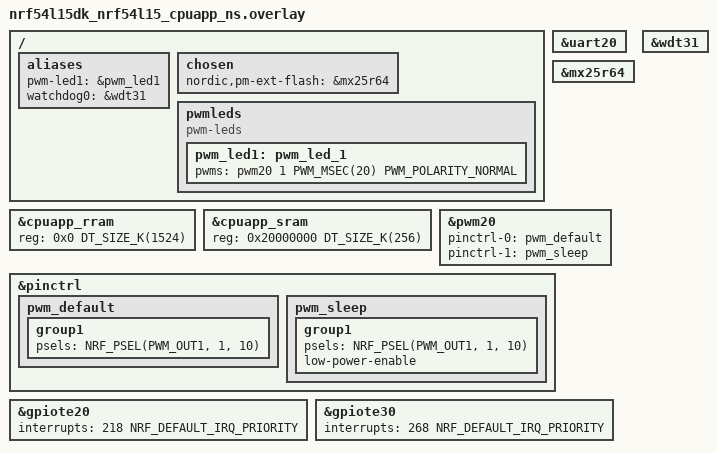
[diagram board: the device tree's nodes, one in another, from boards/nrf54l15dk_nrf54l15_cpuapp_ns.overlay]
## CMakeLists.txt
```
#
# Copyright (c) 2021 Nordic Semiconductor ASA
#
# SPDX-License-Identifier: LicenseRef-Nordic-5-Clause
#

cmake_minimum_required(VERSION 3.20.0)

find_package(Zephyr HINTS $ENV{ZEPHYR_BASE})

project(matter-light-bulb)

# Enable GNU STD support.
include(${ZEPHYR_CONNECTEDHOMEIP_MODULE_DIR}/config/nrfconnect/app/enable-gnu-std.cmake)

# NORDIC SDK APP START

# Include all source files that are located in the Matter common directory.
include(${ZEPHYR_NRF_MODULE_DIR}/samples/matter/common/cmake/source_common.cmake)

# Include Data Model utils
include(${ZEPHYR_NRF_MODULE_DIR}/samples/matter/common/cmake/data_model.cmake)

include(${ZEPHYR_NRF_MODULE_DIR}/samples/matter/common/cmake/zap_helpers.cmake)
ncs_get_zap_parent_dir(ZAP_PARENT_DIR)

target_include_directories(app PRIVATE
    src
    ${ZAP_PARENT_DIR}
)

if(CONFIG_AWS_IOT_INTEGRATION)
    add_subdirectory(src/aws_iot_integration)
endif()

target_sources(app PRIVATE
    src/app_task.cpp
    src/main.cpp
    src/zcl_callbacks.cpp
    ${CHIP_ROOT}/src/app/util/persistence/DeferredAttributePersistenceProvider.cpp
)

ncs_configure_data_model()
# NORDIC SDK APP END
```

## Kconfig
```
#
# Copyright (c) 2022 Nordic Semiconductor
#
# SPDX-License-Identifier: LicenseRef-Nordic-5-Clause
#
mainmenu "Matter nRF Connect Light Bulb Example Application"

# Sample configuration used for Thread networking
if OPENTHREAD

choice OPENTHREAD_NORDIC_LIBRARY_CONFIGURATION
	default OPENTHREAD_NORDIC_LIBRARY_FTD
endchoice

choice OPENTHREAD_DEVICE_TYPE
	default OPENTHREAD_FTD
endchoice

endif # OPENTHREAD

source "${ZEPHYR_CONNECTEDHOMEIP_MODULE_DIR}/config/nrfconnect/chip-module/Kconfig.features"
source "${ZEPHYR_CONNECTEDHOMEIP_MODULE_DIR}/config/nrfconnect/chip-module/Kconfig.defaults"
source "${ZEPHYR_NRF_MODULE_DIR}/samples/matter/common/src/Kconfig"
source "Kconfig.zephyr"
rsource "src/aws_iot_integration/Kconfig"
```

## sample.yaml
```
sample:
  description: Matter Light Bulb example
  name: Matter Light Bulb
tests:
  sample.matter.light_bulb.debug:
    sysbuild: true
    build_only: true
    integration_platforms:
      - nrf52840dk/nrf52840
      - nrf5340dk/nrf5340/cpuapp
      - nrf7002dk/nrf5340/cpuapp
      - nrf54l15dk/nrf54l15/cpuapp
      - nrf54l15dk/nrf54l15/cpuapp/ns
      - nrf54lm20pdk/nrf54lm20a/cpuapp
    platform_allow:
      - nrf52840dk/nrf52840
      - nrf5340dk/nrf5340/cpuapp
      - nrf7002dk/nrf5340/cpuapp
      - nrf54l15dk/nrf54l15/cpuapp
      - nrf54l15dk/nrf54l15/cpuapp/ns
      - nrf54lm20pdk/nrf54lm20a/cpuapp
    tags:
      - sysbuild
      - ci_samples_matter
  sample.matter.light_bulb.release:
    sysbuild: true
    build_only: true
    extra_args:
      - FILE_SUFFIX=release
      - SB_CONFIG_BOOTLOADER_MCUBOOT=y
      - SB_CONFIG_PARTITION_MANAGER=y
    integration_platforms:
      - nrf52840dk/nrf52840
      - nrf5340dk/nrf5340/cpuapp
      - nrf7002dk/nrf5340/cpuapp
      - nrf54l15dk/nrf54l15/cpuapp
      - nrf54lm20pdk/nrf54lm20a/cpuapp
    platform_allow:
      - nrf52840dk/nrf52840
      - nrf5340dk/nrf5340/cpuapp
      - nrf7002dk/nrf5340/cpuapp
      - nrf54l15dk/nrf54l15/cpuapp
      - nrf54lm20pdk/nrf54lm20a/cpuapp
    tags:
      - sysbuild
      - ci_samples_matter
  sample.matter.light_bulb.ffs:
    sysbuild: true
    build_only: true
    extra_args:
      - CONFIG_CHIP_COMMISSIONABLE_DEVICE_TYPE=y
      - CONFIG_CHIP_ROTATING_DEVICE_ID=y
      - CONFIG_CHIP_DEVICE_TYPE=257
    integration_platforms:
      - nrf52840dk/nrf52840
      - nrf5340dk/nrf5340/cpuapp
      - nrf7002dk/nrf5340/cpuapp
      - nrf54l15dk/nrf54l15/cpuapp
      - nrf54lm20pdk/nrf54lm20a/cpuapp
    platform_allow:
      - nrf52840dk/nrf52840
      - nrf5340dk/nrf5340/cpuapp
      - nrf7002dk/nrf5340/cpuapp
      - nrf54l15dk/nrf54l15/cpuapp
      - nrf54lm20pdk/nrf54lm20a/cpuapp
    tags:
      - sysbuild
      - ci_samples_matter
  sample.matter.light_bulb.debug.nrf21540ek:
    sysbuild: true
    build_only: true
    extra_args:
      - light_bulb_SHIELD=nrf21540ek
    integration_platforms:
      - nrf52840dk/nrf52840
    platform_allow: nrf52840dk/nrf52840
    tags:
      - sysbuild
      - ci_samples_matter
  sample.matter.light_bulb.debug.nrf21540ek_fwd:
    sysbuild: true
    build_only: true
    extra_args:
      - light_bulb_SHIELD=nrf21540ek
      - ipc_radio_SHIELD=nrf21540ek
    integration_platforms:
      - nrf5340dk/nrf5340/cpuapp
    platform_allow: nrf5340dk/nrf5340/cpuapp
    tags:
      - sysbuild
      - ci_samples_matter
  # Sample to execute load tests
  sample.matter.light_bulb.memory_profiling.persistent_subscriptions:
    sysbuild: true
    build_only: true
    extra_args:
      - CONFIG_CHIP_PERSISTENT_SUBSCRIPTIONS=y
      - CONFIG_CHIP_MEMORY_PROFILING=y
      - CONFIG_SHELL_MINIMAL=y
    platform_allow:
      - nrf52840dk/nrf52840
      - nrf5340dk/nrf5340/cpuapp
      - nrf54l15dk/nrf54l15/cpuapp
      - nrf7002dk/nrf5340/cpuapp
      - nrf54lm20pdk/nrf54lm20a/cpuapp
    integration_platforms:
      - nrf52840dk/nrf52840
      - nrf5340dk/nrf5340/cpuapp
      - nrf54l15dk/nrf54l15/cpuapp
      - nrf7002dk/nrf5340/cpuapp
      - nrf54lm20pdk/nrf54lm20a/cpuapp
    tags:
      - sysbuild
      - ci_samples_matter
  sample.matter.light_bulb.aws:
    sysbuild: true
    build_only: true
    extra_args:
      - EXTRA_CONF_FILE="overlay-aws-iot-integration.conf"
    platform_allow: nrf7002dk/nrf5340/cpuapp
    integration_platforms:
      - nrf7002dk/nrf5340/cpuapp
    tags:
      - sysbuild
      - ci_samples_matter
```

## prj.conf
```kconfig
#
# Copyright (c) 2022 Nordic Semiconductor ASA
#
# SPDX-License-Identifier: LicenseRef-Nordic-5-Clause
#

# Enable CHIP
CONFIG_CHIP=y
CONFIG_CHIP_PROJECT_CONFIG="src/chip_project_config.h"

# Configure ZAP file name
CONFIG_NCS_SAMPLE_MATTER_ZAP_FILE_PATH="${APPLICATION_CONFIG_DIR}/src/default_zap/light_bulb.zap"

# 32773 == 0x8005 (example lighting-app)
CONFIG_CHIP_DEVICE_PRODUCT_ID=32773
CONFIG_STD_CPP17=y

# Enable Matter pairing automatically on application start.
CONFIG_CHIP_ENABLE_PAIRING_AUTOSTART=y

# Enable Matter extended announcement and increase duration to 1 hour.
CONFIG_CHIP_BLE_EXT_ADVERTISING=y
CONFIG_CHIP_BLE_ADVERTISING_DURATION=60

# Add support for LEDs and buttons on Nordic development kits
CONFIG_DK_LIBRARY=y
CONFIG_PWM=y

# Bluetooth Low Energy configuration
CONFIG_BT_DEVICE_NAME="MatterLight"

# Other settings
CONFIG_THREAD_NAME=y
CONFIG_MPU_STACK_GUARD=y
CONFIG_RESET_ON_FATAL_ERROR=n
CONFIG_CHIP_LIB_SHELL=y
CONFIG_NCS_SAMPLE_MATTER_TEST_SHELL=y

# Reduce application size
CONFIG_USE_SEGGER_RTT=n

# Enable Factory Data feature
CONFIG_CHIP_FACTORY_DATA=y
CONFIG_CHIP_FACTORY_DATA_BUILD=y
```

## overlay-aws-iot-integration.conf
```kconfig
#
# Copyright (c) 2023 Nordic Semiconductor ASA
#
# SPDX-License-Identifier: LicenseRef-Nordic-5-Clause
#

# Enable matter integration layer
CONFIG_AWS_IOT_INTEGRATION=y
CONFIG_AWS_IOT_INTEGRATION_LOG_LEVEL_DBG=y

# AWS IoT library
CONFIG_AWS_IOT=y
CONFIG_AWS_IOT_BROKER_HOST_NAME="xxx.amazonaws.com"
CONFIG_AWS_IOT_CLIENT_ID_STATIC="my-thing"
CONFIG_AWS_IOT_AUTO_DEVICE_SHADOW_REQUEST=n
CONFIG_AWS_IOT_TOPIC_UPDATE_DELTA_SUBSCRIBE=y

# JSON
CONFIG_JSON_LIBRARY=y

# MQTT helper library
CONFIG_MQTT_HELPER_PROVISION_CERTIFICATES=y
CONFIG_MQTT_HELPER_CERTIFICATES_FOLDER="src/aws_iot_integration/certs"
CONFIG_MQTT_HELPER_SEC_TAG=201

# MQTT - Maximum MQTT keepalive timeout specified by AWS IoT Core
CONFIG_MQTT_KEEPALIVE=1200
CONFIG_MQTT_CLEAN_SESSION=y

# MBed TLS
CONFIG_MBEDTLS_HEAP_SIZE=98304
CONFIG_MBEDTLS_RSA_C=y
CONFIG_MBEDTLS_SHA384_C=y
CONFIG_MBEDTLS_SSL_OUT_CONTENT_LEN=1024

# PSA
CONFIG_PSA_WANT_KEY_TYPE_RSA_PUBLIC_KEY=y
CONFIG_PSA_WANT_RSA_KEY_SIZE_2048=y

# Zephyr Networking
CONFIG_NET_CONNECTION_MANAGER=y
CONFIG_NET_DHCPV4=y
CONFIG_NET_IPV4=y
CONFIG_NET_TCP=y
CONFIG_NET_SOCKETS_SOCKOPT_TLS=y
CONFIG_NET_MAX_CONN=8
CONFIG_ZVFS_OPEN_MAX=25

# DNS
CONFIG_ZVFS_EVENTFD_MAX=2
CONFIG_DNS_RESOLVER=y

# Adjust NET configurations to reduce the likelyhood of congestion in the TCP stack when there are
# multiple NET users in the system.
CONFIG_NET_PKT_RX_COUNT=14
CONFIG_NET_PKT_TX_COUNT=14
CONFIG_NET_BUF_RX_COUNT=54
CONFIG_NET_BUF_TX_COUNT=54
CONFIG_NET_TCP_MAX_SEND_WINDOW_SIZE=1024

# Free some memory
CONFIG_SHELL=n
CONFIG_CHIP_LIB_SHELL=n
CONFIG_ASSERT=n
CONFIG_LTO=y
CONFIG_ISR_TABLES_LOCAL_DECLARATION=y
```

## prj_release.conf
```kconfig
#
# Copyright (c) 2022 Nordic Semiconductor ASA
#
# SPDX-License-Identifier: LicenseRef-Nordic-5-Clause
#

# Enable CHIP
CONFIG_CHIP=y
CONFIG_CHIP_PROJECT_CONFIG="src/chip_project_config.h"

# Configure ZAP file name
CONFIG_NCS_SAMPLE_MATTER_ZAP_FILE_PATH="${APPLICATION_CONFIG_DIR}/src/default_zap/light_bulb.zap"

# 32773 == 0x8005 (example lighting-app)
CONFIG_CHIP_DEVICE_PRODUCT_ID=32773
CONFIG_STD_CPP17=y

# Enable Matter pairing automatically on application start.
CONFIG_CHIP_ENABLE_PAIRING_AUTOSTART=y

# Enable Matter extended announcement and increase duration to 1 hour.
CONFIG_CHIP_BLE_EXT_ADVERTISING=y
CONFIG_CHIP_BLE_ADVERTISING_DURATION=60

# Add support for LEDs and buttons on Nordic development kits
CONFIG_DK_LIBRARY=y
CONFIG_PWM=y

# Bluetooth Low Energy configuration
CONFIG_BT_DEVICE_NAME="MatterLight"

# Enable system reset on fatal error
CONFIG_RESET_ON_FATAL_ERROR=y

# Disable all debug features
CONFIG_USE_SEGGER_RTT=n
CONFIG_SHELL=n
CONFIG_OPENTHREAD_SHELL=n
CONFIG_CONSOLE=n
CONFIG_UART_CONSOLE=n
CONFIG_SERIAL=n
CONFIG_LOG=n
CONFIG_LOG_MODE_MINIMAL=n
CONFIG_ASSERT_VERBOSE=n
CONFIG_ASSERT_NO_FILE_INFO=y
CONFIG_PRINTK=n
CONFIG_PRINTK_SYNC=n
CONFIG_THREAD_NAME=n
CONFIG_BOOT_BANNER=n

# Enable Factory Data feature
CONFIG_CHIP_FACTORY_DATA=y
CONFIG_CHIP_FACTORY_DATA_BUILD=y

# Enable Watchdog
CONFIG_NCS_SAMPLE_MATTER_WATCHDOG=y

# Enable LTO to decrease the flash usage.
CONFIG_LTO=y
CONFIG_ISR_TABLES_LOCAL_DECLARATION=y
```

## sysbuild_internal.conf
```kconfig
#
# Copyright (c) 2024 Nordic Semiconductor
#
# SPDX-License-Identifier: LicenseRef-Nordic-5-Clause
#

SB_CONFIG_MATTER=y
SB_CONFIG_PM_OVERRIDE_EXTERNAL_DRIVER_CHECK=n
SB_CONFIG_PM_EXTERNAL_FLASH_MCUBOOT_SECONDARY=n

# Enable the DFU image compression.
SB_CONFIG_MCUBOOT_MODE_OVERWRITE_ONLY=y
SB_CONFIG_MCUBOOT_COMPRESSED_IMAGE_SUPPORT=y
```

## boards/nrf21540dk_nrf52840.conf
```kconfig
#
# Copyright (c) 2022 Nordic Semiconductor ASA
#
# SPDX-License-Identifier: LicenseRef-Nordic-5-Clause
#

# This sample uses Kconfig.defaults to set options common for all
# samples. This file should contain only options specific for this sample
# or overrides of default values.

# Other settings
CONFIG_THREAD_NAME=y
CONFIG_MPU_STACK_GUARD=y
CONFIG_RESET_ON_FATAL_ERROR=n
CONFIG_CHIP_LIB_SHELL=y

# Disable Matter OTA DFU
CONFIG_CHIP_OTA_REQUESTOR=n

# Disable QSPI NOR
CONFIG_CHIP_QSPI_NOR=n

# Disable Factory data feature
CONFIG_CHIP_FACTORY_DATA=n
CONFIG_CHIP_FACTORY_DATA_BUILD=n
```

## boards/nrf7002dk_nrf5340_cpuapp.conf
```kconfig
#
# Copyright (c) 2025 Nordic Semiconductor ASA
#
# SPDX-License-Identifier: LicenseRef-Nordic-5-Clause
#

# Enable LTO to decrease the flash usage.
CONFIG_LTO=y
CONFIG_ISR_TABLES_LOCAL_DECLARATION=y
```

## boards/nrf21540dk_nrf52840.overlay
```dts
/*
 * Copyright (c) 2021-2022 Nordic Semiconductor ASA
 *
 * SPDX-License-Identifier: LicenseRef-Nordic-5-Clause
 */

/ {
	/*
	* By default, PWM module is only configured for led0 (LED1 on the board).
	* The light bulb app, however, uses LED2 to show the state of the lighting,
	* including its brightness level.
	*/
	aliases {
		pwm-led1 = &pwm_led1;
	};

	pwmleds {
		pwm_led1: pwm_led_1 {
			pwms = <&pwm0 1 PWM_MSEC(20) PWM_POLARITY_INVERTED>;
		};
	};

};

&pwm0 {
	pinctrl-0 = <&pwm0_default_alt>;
	pinctrl-1 = <&pwm0_sleep_alt>;
	pinctrl-names = "default", "sleep";
};

&pinctrl {
	pwm0_default_alt: pwm0_default_alt {
		group1 {
			psels = <NRF_PSEL(PWM_OUT1, 0, 14)>;
			nordic,invert;
		};
	};

	pwm0_sleep_alt: pwm0_sleep_alt {
		group1 {
			psels = <NRF_PSEL(PWM_OUT1, 0, 14)>;
			low-power-enable;
		};
	};

};

/* Disable unused peripherals to reduce power consumption */
&adc {
	status = "disabled";
};
&uart1 {
	status = "disabled";
};
&i2c0 {
	status = "disabled";
};
&spi1 {
	status = "disabled";
};
&spi3 {
	status = "disabled";
};
&usbd {
	status = "disabled";
};
```

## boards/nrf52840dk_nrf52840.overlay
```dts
/*
 * Copyright (c) 2021-2022 Nordic Semiconductor ASA
 *
 * SPDX-License-Identifier: LicenseRef-Nordic-5-Clause
 */

/ {
	chosen {
		nordic,pm-ext-flash = &mx25r64;
	};

	/*
	* By default, PWM module is only configured for led0 (LED1 on the board).
	* The light bulb app, however, uses LED2 to show the state of the lighting,
	* including its brightness level.
	*/
	aliases {
		pwm-led1 = &pwm_led1;
	};

	pwmleds {
		pwm_led1: pwm_led_1 {
			pwms = <&pwm0 1 PWM_MSEC(20) PWM_POLARITY_INVERTED>;
		};
	};

};

&pwm0 {
	pinctrl-0 = <&pwm0_default_alt>;
	pinctrl-1 = <&pwm0_sleep_alt>;
	pinctrl-names = "default", "sleep";
};

&pinctrl {
	pwm0_default_alt: pwm0_default_alt {
		group1 {
			psels = <NRF_PSEL(PWM_OUT1, 0, 14)>;
			nordic,invert;
		};
	};

	pwm0_sleep_alt: pwm0_sleep_alt {
		group1 {
			psels = <NRF_PSEL(PWM_OUT1, 0, 14)>;
			low-power-enable;
		};
	};

};

/* Disable unused peripherals to reduce power consumption */
&adc {
	status = "disabled";
};
&uart1 {
	status = "disabled";
};
&i2c0 {
	status = "disabled";
};
&spi1 {
	status = "disabled";
};
&spi3 {
	status = "disabled";
};
&usbd {
	status = "disabled";
};
```

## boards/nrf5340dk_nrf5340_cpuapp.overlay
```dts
/*
 * Copyright (c) 2021-2022 Nordic Semiconductor ASA
 *
 * SPDX-License-Identifier: LicenseRef-Nordic-5-Clause
 */

#include <zephyr/dt-bindings/ipc_service/static_vrings.h>

/ {
	chosen {
		nordic,pm-ext-flash = &mx25r64;
	};

	/*
	* By default, PWM module is only configured for led0 (LED1 on the board).
	* The light bulb app, however, uses LED2 to show the state of the lighting,
	* including its brightness level.
	*/
	aliases {
		pwm-led1 = &pwm_led1;
	};

	pwmleds {
		compatible = "pwm-leds";
		pwm_led1: pwm_led_1 {
			pwms = < &pwm0 1 PWM_MSEC(20) PWM_POLARITY_INVERTED>;
		};
	};
};

/* Set IPC thread priority to the highest value to not collide with other threads. */
&ipc0 {
	zephyr,priority = <0 PRIO_COOP>;
};

&pwm0 {
	pinctrl-0 = <&pwm0_default_alt>;
	pinctrl-1 = <&pwm0_sleep_alt>;
	pinctrl-names = "default", "sleep";
};

&pinctrl {
	pwm0_default_alt: pwm0_default_alt {
		group1 {
			psels = <NRF_PSEL(PWM_OUT1, 0, 29)>;
			nordic,invert;
		};
	};

	pwm0_sleep_alt: pwm0_sleep_alt {
		group1 {
			psels = <NRF_PSEL(PWM_OUT1, 0, 29)>;
			low-power-enable;
		};
	};
};

/* Disable unused peripherals to reduce power consumption */
&adc {
	status = "disabled";
};
&i2c1 {
	status = "disabled";
};
&spi2 {
	status = "disabled";
};
&usbd {
	status = "disabled";
};
```

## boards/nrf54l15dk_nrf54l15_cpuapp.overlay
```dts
/*
 * Copyright (c) 2024 Nordic Semiconductor ASA
 *
 * SPDX-License-Identifier: LicenseRef-Nordic-5-Clause
 */


/ {
	chosen {
		nordic,pm-ext-flash = &mx25r64;
	};

	aliases {
		// Configure PWM module for led1 (LED2 on the board)
		pwm-led1 = &pwm_led1;

		// Use watchdog wdt31 as the application watchdog
		watchdog0 = &wdt31;
	};

	pwmleds {
		compatible = "pwm-leds";
		pwm_led1: pwm_led_1 {
			pwms = <&pwm20 1 PWM_MSEC(20) PWM_POLARITY_NORMAL>;
		};
	};
};

// restore full RRAM and SRAM space - by default some parts are dedicated to FLRP
&cpuapp_rram {
	reg = <0x0 DT_SIZE_K(1524)>;
};

&cpuapp_sram {
	reg = <0x20000000 DT_SIZE_K(256)>;
	ranges = <0x0 0x20000000  0x40000>;
};

// TODO: re-enable HWFC once it's fixed
&uart20 {
	/delete-property/ hw-flow-control;
};

&mx25r64 {
	status = "okay";
};

&pwm20 {
	status = "okay";
	pinctrl-0 = <&pwm_default>;
	pinctrl-1 = <&pwm_sleep>;
	pinctrl-names = "default", "sleep";
};

&pinctrl {
	pwm_default: pwm_default {
		group1 {
			psels = <NRF_PSEL(PWM_OUT1, 1, 10)>;
		};
	};
	pwm_sleep: pwm_sleep {
		group1 {
			psels = <NRF_PSEL(PWM_OUT1, 1, 10)>;
			low-power-enable;
		};
	};
};

&wdt31 {
	status = "okay";
};
```

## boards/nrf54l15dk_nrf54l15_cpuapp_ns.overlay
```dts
/*
 * Copyright (c) 2024 Nordic Semiconductor ASA
 *
 * SPDX-License-Identifier: LicenseRef-Nordic-5-Clause
 */

/ {
	aliases {
		// Configure PWM module for led1 (LED2 on the board)
		pwm-led1 = &pwm_led1;

		// Use watchdog wdt31 as the application watchdog
		watchdog0 = &wdt31;
	};

	chosen {
		nordic,pm-ext-flash = &mx25r64;
	};

	pwmleds {
		compatible = "pwm-leds";
		pwm_led1: pwm_led_1 {
			pwms = <&pwm20 1 PWM_MSEC(20) PWM_POLARITY_NORMAL>;
		};
	};
};

// restore full RRAM and SRAM space - by default some parts are dedicated to FLRP
&cpuapp_rram {
	reg = <0x0 DT_SIZE_K(1524)>;
};

&cpuapp_sram {
	reg = <0x20000000 DT_SIZE_K(256)>;
	ranges = <0x0 0x20000000  0x40000>;
};

// TODO: re-enable HWFC once it's fixed
&uart20 {
	/delete-property/ hw-flow-control;
};

&mx25r64 {
	status = "okay";
};

&pwm20 {
	status = "okay";
	pinctrl-0 = <&pwm_default>;
	pinctrl-1 = <&pwm_sleep>;
	pinctrl-names = "default", "sleep";
};

&pinctrl {
	pwm_default: pwm_default {
		group1 {
			psels = <NRF_PSEL(PWM_OUT1, 1, 10)>;
		};
	};
	pwm_sleep: pwm_sleep {
		group1 {
			psels = <NRF_PSEL(PWM_OUT1, 1, 10)>;
			low-power-enable;
		};
	};
};

&wdt31 {
	status = "okay";
};

// Change IRQ ids to handle button interrupts.

// The default values for nRF54L15 are 219 and 269,
// but with TF-M they are reserved for the secure domain
// (218 and 268 are reserved for the non-secure domain).
&gpiote20 {
	interrupts = <218 NRF_DEFAULT_IRQ_PRIORITY>;
};

&gpiote30 {
	interrupts = <268 NRF_DEFAULT_IRQ_PRIORITY>;
};
```

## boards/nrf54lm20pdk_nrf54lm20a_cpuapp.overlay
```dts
/*
 * Copyright (c) 2025 Nordic Semiconductor ASA
 *
 * SPDX-License-Identifier: LicenseRef-Nordic-5-Clause
 */

/ {
	chosen {
		nordic,pm-ext-flash = &mx25r64;
	};

	aliases {
		// Configure PWM module for led1 (LED2 on the board)
		pwm-led1 = &pwm_led1;

		// Use watchdog wdt31 as the application watchdog
		watchdog0 = &wdt31;
	};

	pwmleds {
		compatible = "pwm-leds";
		pwm_led1: pwm_led_1 {
			pwms = <&pwm20 1 PWM_MSEC(20) PWM_POLARITY_NORMAL>;
		};
	};
};

// restore full RRAM and SRAM space - by default some parts are dedicated to FLRP
&cpuapp_rram {
	reg = <0x0 DT_SIZE_K(2036)>;
};

&cpuapp_sram {
	reg = <0x20000000 DT_SIZE_K(512)>;
	ranges = <0x0 0x20000000  0x80000>;
};

&pwm20 {
	status = "okay";
	pinctrl-0 = <&pwm_default>;
	pinctrl-1 = <&pwm_sleep>;
	pinctrl-names = "default", "sleep";
};

&pinctrl {
	pwm_default: pwm_default {
		group1 {
			psels = <NRF_PSEL(PWM_OUT1, 1, 10)>;
		};
	};
	pwm_sleep: pwm_sleep {
		group1 {
			psels = <NRF_PSEL(PWM_OUT1, 1, 10)>;
			low-power-enable;
		};
	};
};

&mx25r64 {
	status = "okay";
};

&wdt31 {
	status = "okay";
};
```

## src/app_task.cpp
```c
/*
 * Copyright (c) 2021 Nordic Semiconductor ASA
 *
 * SPDX-License-Identifier: LicenseRef-Nordic-5-Clause
 */

#include "app_task.h"

#ifdef CONFIG_AWS_IOT_INTEGRATION
#include "aws_iot_integration.h"
#endif

#include "app/matter_init.h"
#include "app/task_executor.h"

#if defined(CONFIG_PWM)
#include "pwm/pwm_device.h"
#endif

#include <app-common/zap-generated/attributes/Accessors.h>
#include <app/clusters/identify-server/identify-server.h>
#include <app/server/Server.h>
#include <app/util/persistence/DefaultAttributePersistenceProvider.h>
#include <app/util/persistence/DeferredAttributePersistenceProvider.h>
#include <setup_payload/OnboardingCodesUtil.h>

#include <zephyr/logging/log.h>

LOG_MODULE_DECLARE(app, CONFIG_CHIP_APP_LOG_LEVEL);

using namespace ::chip;
using namespace ::chip::app;
using namespace ::chip::DeviceLayer;

namespace
{
constexpr EndpointId kLightEndpointId = 1;
constexpr uint8_t kDefaultMinLevel = 0;
constexpr uint8_t kDefaultMaxLevel = 254;
constexpr uint16_t kTriggerEffectTimeout = 5000;
constexpr uint16_t kTriggerEffectFinishTimeout = 1000;

k_timer sTriggerEffectTimer;

Identify sIdentify = { kLightEndpointId, AppTask::IdentifyStartHandler, AppTask::IdentifyStopHandler,
		       Clusters::Identify::IdentifyTypeEnum::kVisibleIndicator, AppTask::TriggerIdentifyEffectHandler };

bool sIsTriggerEffectActive = false;

#if defined(CONFIG_PWM)
const struct pwm_dt_spec sLightPwmDevice = PWM_DT_SPEC_GET(DT_ALIAS(pwm_led1));
#endif

// Define a custom attribute persister which makes actual write of the CurrentLevel attribute value
// to the non-volatile storage only when it has remained constant for 5 seconds. This is to reduce
// the flash wearout when the attribute changes frequently as a result of MoveToLevel command.
// DeferredAttribute object describes a deferred attribute, but also holds a buffer with a value to
// be written, so it must live so long as the DeferredAttributePersistenceProvider object.
DeferredAttribute gCurrentLevelPersister(ConcreteAttributePath(kLightEndpointId, Clusters::LevelControl::Id,
							       Clusters::LevelControl::Attributes::CurrentLevel::Id));

// Deferred persistence will be auto-initialized as soon as the default persistence is initialized
DefaultAttributePersistenceProvider gSimpleAttributePersistence;
DeferredAttributePersistenceProvider gDeferredAttributePersister(gSimpleAttributePersistence,
								 Span<DeferredAttribute>(&gCurrentLevelPersister, 1),
								 System::Clock::Milliseconds32(5000));

#define APPLICATION_BUTTON_MASK DK_BTN2_MSK
} /* namespace */

void AppTask::IdentifyStartHandler(Identify *)
{
	Nrf::PostTask(
		[] { Nrf::GetBoard().GetLED(Nrf::DeviceLeds::LED2).Blink(Nrf::LedConsts::kIdentifyBlinkRate_ms); });
}

void AppTask::IdentifyStopHandler(Identify *)
{
	Nrf::PostTask([] {
		Nrf::GetBoard().GetLED(Nrf::DeviceLeds::LED2).Set(false);

#if defined(CONFIG_PWM)
		Instance().mPWMDevice.ApplyLevel();
#endif
	});
}

void AppTask::TriggerEffectTimerTimeoutCallback(k_timer *timer)
{
	LOG_INF("Identify effect completed");

	sIsTriggerEffectActive = false;

	Nrf::GetBoard().GetLED(Nrf::DeviceLeds::LED2).Set(false);

#if defined(CONFIG_PWM)
	Instance().mPWMDevice.ApplyLevel();
#endif
}

void AppTask::TriggerIdentifyEffectHandler(Identify *identify)
{
	switch (identify->mCurrentEffectIdentifier) {
	/* Just handle all effects in the same way. */
	case Clusters::Identify::EffectIdentifierEnum::kBlink:
	case Clusters::Identify::EffectIdentifierEnum::kBreathe:
	case Clusters::Identify::EffectIdentifierEnum::kOkay:
	case Clusters::Identify::EffectIdentifierEnum::kChannelChange:
		LOG_INF("Identify effect identifier changed to %d",
			static_cast<uint8_t>(identify->mCurrentEffectIdentifier));

		sIsTriggerEffectActive = false;

		k_timer_stop(&sTriggerEffectTimer);
		k_timer_start(&sTriggerEffectTimer, K_MSEC(kTriggerEffectTimeout), K_NO_WAIT);

#if defined(CONFIG_PWM)
		Instance().mPWMDevice.SuppressOutput();
#endif
		Nrf::GetBoard().GetLED(Nrf::DeviceLeds::LED2).Blink(Nrf::LedConsts::kIdentifyBlinkRate_ms);

		break;
	case Clusters::Identify::EffectIdentifierEnum::kFinishEffect:
		LOG_INF("Identify effect finish triggered");
		k_timer_stop(&sTriggerEffectTimer);
		k_timer_start(&sTriggerEffectTimer, K_MSEC(kTriggerEffectFinishTimeout), K_NO_WAIT);
		break;
	case Clusters::Identify::EffectIdentifierEnum::kStopEffect:
		if (sIsTriggerEffectActive) {
			sIsTriggerEffectActive = false;

			k_timer_stop(&sTriggerEffectTimer);

			Nrf::GetBoard().GetLED(Nrf::DeviceLeds::LED2).Set(false);

#if defined(CONFIG_PWM)
			Instance().mPWMDevice.ApplyLevel();
#endif
		}
		break;
	default:
		LOG_ERR("Received invalid effect identifier.");
		break;
	}
}

void AppTask::LightingActionEventHandler(const LightingEvent &event)
{
#if defined(CONFIG_PWM)
	Nrf::PWMDevice::Action_t action = Nrf::PWMDevice::INVALID_ACTION;
	int32_t actor = 0;
	if (event.Actor == LightingActor::Button) {
		action = Instance().mPWMDevice.IsTurnedOn() ? Nrf::PWMDevice::OFF_ACTION : Nrf::PWMDevice::ON_ACTION;
		actor = static_cast<int32_t>(event.Actor);
	}

	if (action == Nrf::PWMDevice::INVALID_ACTION || !Instance().mPWMDevice.InitiateAction(action, actor, NULL)) {
		LOG_INF("An action could not be initiated.");
	}
#else
	Nrf::GetBoard().GetLED(Nrf::DeviceLeds::LED2).Set(!Nrf::GetBoard().GetLED(Nrf::DeviceLeds::LED2).GetState());
#endif
}

void AppTask::ButtonEventHandler(Nrf::ButtonState state, Nrf::ButtonMask hasChanged)
{
	if ((APPLICATION_BUTTON_MASK & hasChanged) & state) {
		Nrf::PostTask([] {
			LightingEvent event;
			event.Actor = LightingActor::Button;
			LightingActionEventHandler(event);
		});
	}
}

#ifdef CONFIG_AWS_IOT_INTEGRATION
bool AppTask::AWSIntegrationCallback(struct aws_iot_integration_cb_data *data)
{
	LOG_INF("Attribute change requested from AWS IoT: %d", data->value);

	Protocols::InteractionModel::Status status;

	VerifyOrDie(data->error == 0);

	if (data->attribute_id == ATTRIBUTE_ID_ONOFF) {
		/* write the new on/off value */
		status = Clusters::OnOff::Attributes::OnOff::Set(kLightEndpointId, data->value);
		if (status != Protocols::InteractionModel::Status::Success) {
			LOG_ERR("Updating on/off cluster failed: %x", to_underlying(status));
			return false;
		}
	} else if (data->attribute_id == ATTRIBUTE_ID_LEVEL_CONTROL) {
		/* write the current level */
		status = Clusters::LevelControl::Attributes::CurrentLevel::Set(kLightEndpointId, data->value);

		if (status != Protocols::InteractionModel::Status::Success) {
			LOG_ERR("Updating level cluster failed: %x", to_underlying(status));
			return false;
		}
	}

	return true;
}
#endif /* CONFIG_AWS_IOT_INTEGRATION */

#if defined(CONFIG_PWM)
void AppTask::ActionInitiated(Nrf::PWMDevice::Action_t action, int32_t actor)
{
	if (action == Nrf::PWMDevice::ON_ACTION) {
		LOG_INF("Turn On Action has been initiated");
	} else if (action == Nrf::PWMDevice::OFF_ACTION) {
		LOG_INF("Turn Off Action has been initiated");
	} else if (action == Nrf::PWMDevice::LEVEL_ACTION) {
		LOG_INF("Level Action has been initiated");
	}
}

void AppTask::ActionCompleted(Nrf::PWMDevice::Action_t action, int32_t actor)
{
	if (action == Nrf::PWMDevice::ON_ACTION) {
		LOG_INF("Turn On Action has been completed");
	} else if (action == Nrf::PWMDevice::OFF_ACTION) {
		LOG_INF("Turn Off Action has been completed");
	} else if (action == Nrf::PWMDevice::LEVEL_ACTION) {
		LOG_INF("Level Action has been completed");
	}

	if (actor == static_cast<int32_t>(LightingActor::Button)) {
		Instance().UpdateClusterState();
	}
}
#endif /* CONFIG_PWM */

void AppTask::UpdateClusterState()
{
	SystemLayer().ScheduleLambda([this] {
#if defined(CONFIG_PWM)
		/* write the new on/off value */
		Protocols::InteractionModel::Status status =
			Clusters::OnOff::Attributes::OnOff::Set(kLightEndpointId, mPWMDevice.IsTurnedOn());
#else
		Protocols::InteractionModel::Status status = Clusters::OnOff::Attributes::OnOff::Set(
			kLightEndpointId, Nrf::GetBoard().GetLED(Nrf::DeviceLeds::LED2).GetState());
#endif
		if (status != Protocols::InteractionModel::Status::Success) {
			LOG_ERR("Updating on/off cluster failed: %x", to_underlying(status));
		}

#if defined(CONFIG_PWM)
		/* write the current level */
		status = Clusters::LevelControl::Attributes::CurrentLevel::Set(kLightEndpointId, mPWMDevice.GetLevel());
#else
		/* write the current level */
		if (Nrf::GetBoard().GetLED(Nrf::DeviceLeds::LED2).GetState()) {
			status = Clusters::LevelControl::Attributes::CurrentLevel::Set(kLightEndpointId, 100);
		} else {
			status = Clusters::LevelControl::Attributes::CurrentLevel::Set(kLightEndpointId, 0);
		}
#endif

		if (status != Protocols::InteractionModel::Status::Success) {
			LOG_ERR("Updating level cluster failed: %x", to_underlying(status));
		}
	});
}

void AppTask::InitPWMDDevice()
{
#if defined(CONFIG_PWM)
	/* Initialize lighting device (PWM) */
	uint8_t minLightLevel = kDefaultMinLevel;
	Clusters::LevelControl::Attributes::MinLevel::Get(kLightEndpointId, &minLightLevel);

	uint8_t maxLightLevel = kDefaultMaxLevel;
	Clusters::LevelControl::Attributes::MaxLevel::Get(kLightEndpointId, &maxLightLevel);

	Clusters::LevelControl::Attributes::CurrentLevel::TypeInfo::Type currentLevel;
	Clusters::LevelControl::Attributes::CurrentLevel::Get(kLightEndpointId, currentLevel);

	int ret =
		mPWMDevice.Init(&sLightPwmDevice, minLightLevel, maxLightLevel, currentLevel.ValueOr(kDefaultMaxLevel));
	if (ret != 0) {
		LOG_ERR("Failed to initialize PWD device.");
	}

	mPWMDevice.SetCallbacks(ActionInitiated, ActionCompleted);
#endif
}

CHIP_ERROR AppTask::Init()
{
	/* Initialize Matter stack */
	ReturnErrorOnFailure(Nrf::Matter::PrepareServer(Nrf::Matter::InitData{ .mPostServerInitClbk = [] {
		app::SetAttributePersistenceProvider(&gDeferredAttributePersister);
		return CHIP_NO_ERROR;
	} }));

	if (!Nrf::GetBoard().Init(ButtonEventHandler)) {
		LOG_ERR("User interface initialization failed.");
		return CHIP_ERROR_INCORRECT_STATE;
	}

	/* Register Matter event handler that controls the connectivity status LED based on the captured Matter network
	 * state. */
	ReturnErrorOnFailure(Nrf::Matter::RegisterEventHandler(Nrf::Board::DefaultMatterEventHandler, 0));

#ifdef CONFIG_AWS_IOT_INTEGRATION
	int retAws = aws_iot_integration_register_callback(AWSIntegrationCallback);
	if (retAws) {
		LOG_ERR("aws_iot_integration_register_callback() failed");
		return chip::System::MapErrorZephyr(retAws);
	}
#endif

	/* Initialize trigger effect timer */
	k_timer_init(&sTriggerEffectTimer, &AppTask::TriggerEffectTimerTimeoutCallback, nullptr);

	return Nrf::Matter::StartServer();
}

CHIP_ERROR AppTask::StartApp()
{
	ReturnErrorOnFailure(Init());

	while (true) {
		Nrf::DispatchNextTask();
	}

	return CHIP_NO_ERROR;
}
```

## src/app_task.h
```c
/*
 * Copyright (c) 2021 Nordic Semiconductor ASA
 *
 * SPDX-License-Identifier: LicenseRef-Nordic-5-Clause
 */

#pragma once

#include "board/board.h"
#include "pwm/pwm_device.h"

#include <platform/CHIPDeviceLayer.h>

struct k_timer;
struct Identify;

enum class LightingActor : uint8_t { Remote, Button };

struct LightingEvent {
	uint8_t Action;
	LightingActor Actor;
};

class AppTask {
public:
	static AppTask &Instance()
	{
		static AppTask sAppTask;
		return sAppTask;
	};

	CHIP_ERROR StartApp();

	void UpdateClusterState();
	void InitPWMDDevice();
	Nrf::PWMDevice &GetPWMDevice() { return mPWMDevice; }

	static void IdentifyStartHandler(Identify *);
	static void IdentifyStopHandler(Identify *);
	static void TriggerIdentifyEffectHandler(Identify *);
	static void TriggerEffectTimerTimeoutCallback(k_timer *timer);

private:
	CHIP_ERROR Init();

	static void LightingActionEventHandler(const LightingEvent &event);
	static void ButtonEventHandler(Nrf::ButtonState state, Nrf::ButtonMask hasChanged);

	static void ActionInitiated(Nrf::PWMDevice::Action_t action, int32_t actor);
	static void ActionCompleted(Nrf::PWMDevice::Action_t action, int32_t actor);

#ifdef CONFIG_AWS_IOT_INTEGRATION
	static bool AWSIntegrationCallback(struct aws_iot_integration_cb_data *data);
#endif

	Nrf::PWMDevice mPWMDevice;
};
```

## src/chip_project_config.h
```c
/*
 * Copyright (c) 2021 Nordic Semiconductor ASA
 *
 * SPDX-License-Identifier: LicenseRef-Nordic-5-Clause
 */

/**
 *    @file
 *          Example project configuration file for CHIP.
 *
 *          This is a place to put application or project-specific overrides
 *          to the default configuration values for general CHIP features.
 *
 */

#pragma once

// Reduce some flash space when the CONFIG_CHIP_MEMORY_PROFILING is selected
#ifdef CONFIG_CHIP_MEMORY_PROFILING
#define CHIP_CONFIG_LOG_MODULE_SecureChannel_PROGRESS 0
#define CHIP_CONFIG_LOG_MODULE_FabricProvisioning_PROGRESS 0
#define CHIP_CONFIG_LOG_MODULE_InteractionModel_PROGRESS 0
#define CHIP_CONFIG_LOG_MODULE_InteractionModel_DETAIL 0
#define CHIP_CONFIG_LOG_MODULE_DataManagement_PROGRESS 0
#endif
```

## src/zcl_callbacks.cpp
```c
/*
 * Copyright (c) 2021 Nordic Semiconductor ASA
 *
 * SPDX-License-Identifier: LicenseRef-Nordic-5-Clause
 */

#include <lib/support/logging/CHIPLogging.h>

#include "app_task.h"

#ifdef CONFIG_AWS_IOT_INTEGRATION
#include "aws_iot_integration.h"
#endif

#include <app-common/zap-generated/attributes/Accessors.h>
#include <app-common/zap-generated/ids/Attributes.h>
#include <app-common/zap-generated/ids/Clusters.h>
#include <app/ConcreteAttributePath.h>

using namespace ::chip;
using namespace ::chip::app::Clusters;
using namespace ::chip::app::Clusters::OnOff;

void MatterPostAttributeChangeCallback(const chip::app::ConcreteAttributePath &attributePath, uint8_t type,
				       uint16_t size, uint8_t *value)
{
	ClusterId clusterId = attributePath.mClusterId;
	AttributeId attributeId = attributePath.mAttributeId;

	if (clusterId == OnOff::Id && attributeId == OnOff::Attributes::OnOff::Id) {
		ChipLogProgress(Zcl, "Cluster OnOff: attribute OnOff set to %" PRIu8 "", *value);

#if defined(CONFIG_PWM)
		AppTask::Instance().GetPWMDevice().InitiateAction(*value ? Nrf::PWMDevice::ON_ACTION :
									   Nrf::PWMDevice::OFF_ACTION,
								  static_cast<int32_t>(LightingActor::Remote), value);
#else
		Nrf::GetBoard().GetLED(Nrf::DeviceLeds::LED2).Set(*value);
#endif

#ifdef CONFIG_AWS_IOT_INTEGRATION
		aws_iot_integration_attribute_set(ATTRIBUTE_ID_ONOFF, *value);
#endif

	} else if (clusterId == LevelControl::Id && attributeId == LevelControl::Attributes::CurrentLevel::Id) {
		ChipLogProgress(Zcl, "Cluster LevelControl: attribute CurrentLevel set to %" PRIu8 "", *value);
#if defined(CONFIG_PWM)
		if (AppTask::Instance().GetPWMDevice().IsTurnedOn()) {
			AppTask::Instance().GetPWMDevice().InitiateAction(
				Nrf::PWMDevice::LEVEL_ACTION, static_cast<int32_t>(LightingActor::Remote), value);
		} else {
			ChipLogDetail(Zcl, "LED is off. Try to use move-to-level-with-on-off instead of move-to-level");
		}
#endif

#ifdef CONFIG_AWS_IOT_INTEGRATION
		aws_iot_integration_attribute_set(ATTRIBUTE_ID_LEVEL_CONTROL, *value);
#endif
	}
}

/** @brief OnOff Cluster Init
 *
 * This function is called when a specific cluster is initialized. It gives the
 * application an opportunity to take care of cluster initialization procedures.
 * It is called exactly once for each endpoint where cluster is present.
 *
 * @param endpoint   Ver.: always
 *
 * TODO Issue #3841
 * emberAfOnOffClusterInitCallback happens before the stack initialize the cluster
 * attributes to the default value.
 * The logic here expects something similar to the deprecated Plugins callback
 * emberAfPluginOnOffClusterServerPostInitCallback.
 *
 */
void emberAfOnOffClusterInitCallback(EndpointId endpoint)
{
	Protocols::InteractionModel::Status status;
	bool storedValue;

	/* Read storedValue on/off value */
	status = Attributes::OnOff::Get(endpoint, &storedValue);
	if (status == Protocols::InteractionModel::Status::Success) {
		/* Set actual state to the cluster state that was last persisted */
#if defined(CONFIG_PWM)
		AppTask::Instance().InitPWMDDevice();

		AppTask::Instance().GetPWMDevice().InitiateAction(
			storedValue ? Nrf::PWMDevice::ON_ACTION : Nrf::PWMDevice::OFF_ACTION,
			static_cast<int32_t>(LightingActor::Remote), reinterpret_cast<uint8_t *>(&storedValue));
#else
		Nrf::GetBoard().GetLED(Nrf::DeviceLeds::LED2).Set(storedValue);
#endif
	}

	AppTask::Instance().UpdateClusterState();
}
```
